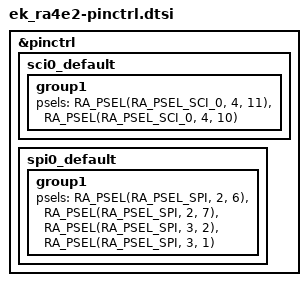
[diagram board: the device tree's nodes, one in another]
/*
 * Copyright (c) 2024 Renesas Electronics Corporation
 * SPDX-License-Identifier: Apache-2.0
 */

&pinctrl {
	sci0_default: sci0_default {
		group1 {
			/* tx rx */
			psels = <RA_PSEL(RA_PSEL_SCI_0, 4, 11)>,
			<RA_PSEL(RA_PSEL_SCI_0, 4, 10)>;
		};
	};

	spi0_default: spi0_default {
		group1 {
			/* MISO MOSI RSPCK SSL */
			psels = <RA_PSEL(RA_PSEL_SPI, 2, 6)>,
			<RA_PSEL(RA_PSEL_SPI, 2, 7)>,
			<RA_PSEL(RA_PSEL_SPI, 3, 2)>,
			<RA_PSEL(RA_PSEL_SPI, 3, 1)>;
		};
	};
};
